# H616 register map
Vendor: Allwinner; Series: H616; File version: 0.1
CPU: other 0, little endian, MPU, no FPU, 0 interrupt priority bits
Registers are 32-bit, read-write, reset 0x0 unless marked. A register's access mark holds for its fields unless they carry their own. Offsets are from the block's base; [hi:lo] are bit positions; lines under a group give offsets from that group; {n}, {i} and the like mark numbered series; 'fields as' and 'values as' point back to an identical list.

## TCON_TV0
Base 0x06515000
Same registers: TCON_TV1 0x06516000
0x00 TV_GCTL_REG — TV Global Control Register
  [31] TV_EN — 0: Disable 1: Enable When it is disabled, the module will be reset to idle state.
    0=Disable; 1=Enable When it is disabled, the module will be reset to idle state
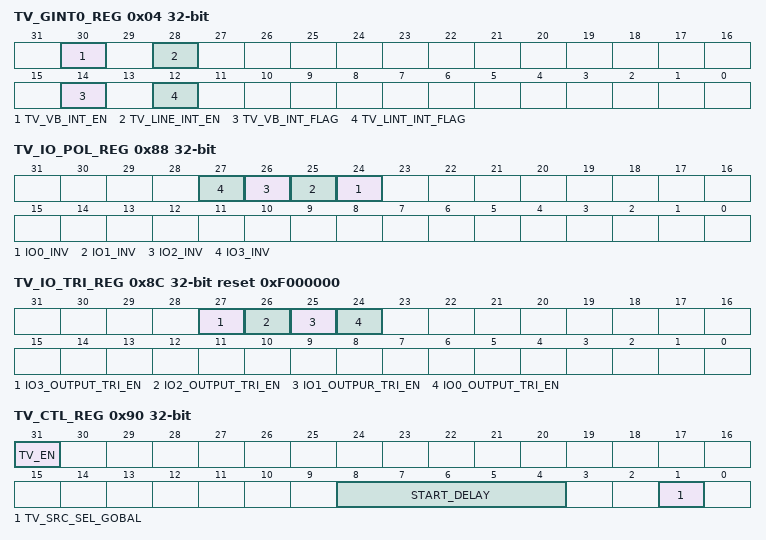
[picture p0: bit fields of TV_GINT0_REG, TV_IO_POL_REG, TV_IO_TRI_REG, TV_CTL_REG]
0x04 TV_GINT0_REG — TV Global Interrupt Register0
  [30] TV_VB_INT_EN — 0: Disable 1: Enable Enable the Vb interrupt.
    0=Disable; 1=Enable Enable the Vb interrupt
  [28] TV_LINE_INT_EN — 0: Disable 1: Enable Enable the line interrupt.
    0=Disable; 1=Enable Enable the line interrupt
  [14] TV_VB_INT_FLAG — Assert during vertical no-display period every frame. Write 0 to clear it.
  [12] TV_LINT_INT_FLAG — Trigger when SY1 match the current TV scan line Write 0 to clear it.
0x08 TV_GINT1_REG — TV Global Interrupt Register1
  [11:0] TV_LINE_INT_NUM — Scan line for TV line trigger(including inactive lines) Setting it for the specified line of trigger 1.
0x40 TV_SRC_CTL_REG — TV Source Control Register
  [2:0] TV_SRC_SEL — 000: DE 001: Color Check 010: Grayscale Check 011: Black by White Check 100: Reserved 101: Reserved 111: Gridding Check
    0=DE; 1=Color Check; 2=Grayscale Check; 3=Black by White Check; 7=Gridding Check
0x88 TV_IO_POL_REG — TV IO Polarity Register
  [n+24] IO{n}_INV (n=0..3) — 0: Not invert 1: Invert Enable invert function of IO{n}.
    0=Not_invert; 1=Invert Enable invert function of IO{n}
0x8C TV_IO_TRI_REG reset 0xF000000 — TV IO Control Register
  [27] IO3_OUTPUT_TRI_EN — 1: Disable 0: Enable Enable the output of IO3.
    1=Disable; 0=Enable Enable the output of IO3
  [26] IO2_OUTPUT_TRI_EN — 1: Disable 0: Enable Enable the output of IO2.
    1=Disable; 0=Enable Enable the output of IO2
  [25] IO1_OUTPUR_TRI_EN — 1: Disable 0: Enable Enable the output of IO1.
    1=Disable; 0=Enable Enable the output of IO1
  [24] IO0_OUTPUT_TRI_EN — 1: Disable 0: Enable Enable the output of IO0.
    1=Disable; 0=Enable Enable the output of IO0
0x90 TV_CTL_REG — TV Control Register
  [31] TV_EN — 0: Disable 1: Enable
    0=Disable; 1=Enable
  [8:4] START_DELAY — This is for DE0 and DE1.
  [1] TV_SRC_SEL_GOBAL — 0: reserved 1: BLUE data
    1=BLUE_data
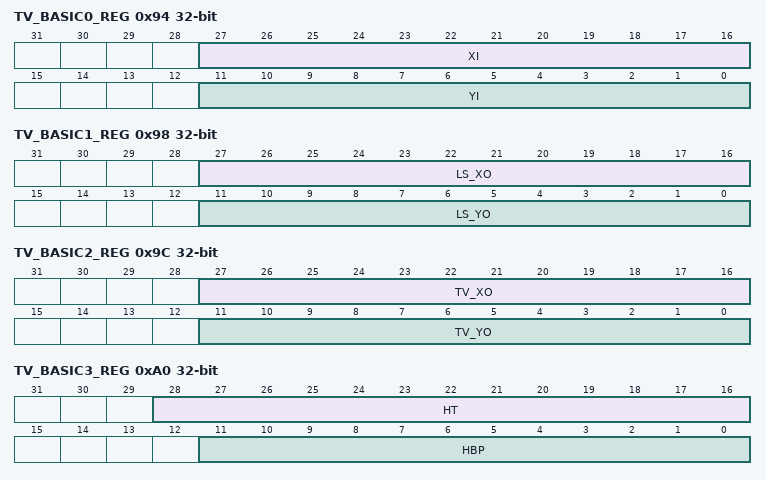
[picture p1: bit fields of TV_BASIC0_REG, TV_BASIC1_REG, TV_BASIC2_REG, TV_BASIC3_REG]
0x94 TV_BASIC0_REG — TV Basic Timing Register0
  [27:16] XI — source width is X+1
  [11:0] YI — source height is Y+1
0x98 TV_BASIC1_REG — TV Basic Timing Register1
  [27:16] LS_XO — Width is LS_XO+1
  [11:0] LS_YO — Width is LS_YO+1
0x9C TV_BASIC2_REG — TV Basic Timing Register2
  [27:16] TV_XO — Width is TV_XO+1
  [11:0] TV_YO — Height is TV_YO+1
0xA0 TV_BASIC3_REG — TV Basic Timing Register3
  [28:16] HT — Horizontal total time T = (HT+1) * T
  [11:0] HBP — Horizontal back porch T = (HBP +1) * T
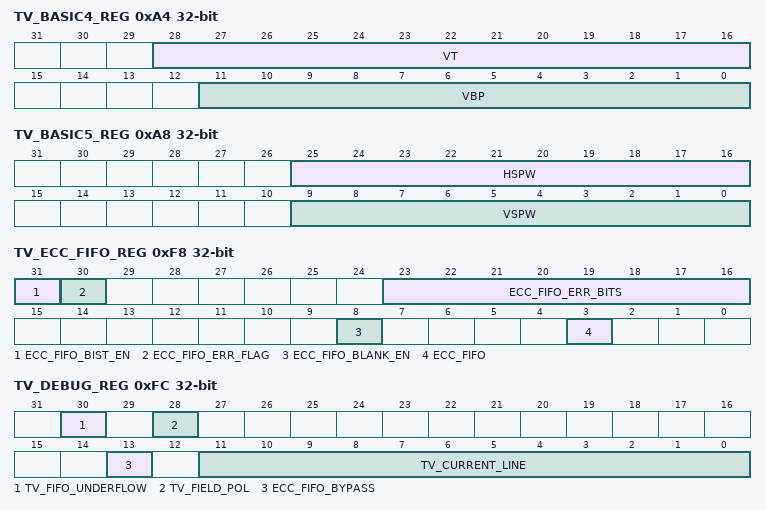
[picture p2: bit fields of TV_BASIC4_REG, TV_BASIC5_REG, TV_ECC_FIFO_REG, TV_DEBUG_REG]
0xA4 TV_BASIC4_REG — TV Basic Timing Register4
  [28:16] VT — Vertical total time (in HD line) T = VT/2 * T
  [11:0] VBP — Vertical back porch (in HD line) T = (VBP +1) * T
0xA8 TV_BASIC5_REG — TV Basic Timing Register5
  [25:16] HSPW — Horizontal Sync Pulse Width (in dclk) T = (HSPW+1) * T HT> (HSPW+1)
  [9:0] VSPW — Vertical Sync Pulse Width (in lines) T = (VSPW+1) * T VT/2 > (VSPW+1)
0xF8 TV_ECC_FIFO_REG — TV ECC FIFO Register
  [31] ECC_FIFO_BIST_EN — 0: Disable 1: Enable Enable ECC FIFO BIST test function.
    0=Disable; 1=Enable Enable ECC FIFO BIST test function
  [30] ECC_FIFO_ERR_FLAG ro — Indicates the error information in ECC FIFO.
  [23:16] ECC_FIFO_ERR_BITS ro — Indicates the error information in ECC FIFO.
  [8] ECC_FIFO_BLANK_EN — 0: Disable ECC function in blanking 1: Enable ECC function in blanking ECC function is tent to trigger in blanking area at HV mode, set `0` when in HV mode.
    0=Disable ECC function in blanking; 1=Enable ECC function in blanking ECC function is tent to trigger in blanking area at HV mode, set `0` when in HV mode
  [3] ECC_FIFO — 0:Enable 1:Disable Enable ECC FIFO function.
0xFC TV_DEBUG_REG — TV Debug Register
  [30] TV_FIFO_UNDERFLOW ro — 0: Not underflow 1: Underflow The flag shows whether the FIFOs in underflow status.
    0=Not_underflow; 1=Underflow The flag shows whether the FIFOs in underflow status
  [28] TV_FIELD_POL ro — 0: Second field 1: First field The flag indicates the current field polarity.
    0=Second; 1=First field The flag indicates the current field polarity
  [13] ECC_FIFO_BYPASS — 0: Used 1: Bypass Setup that whether to bypass ECC FIFO.
    0=Used; 1=Bypass Setup that whether to bypass ECC FIFO
  [11:0] TV_CURRENT_LINE ro — Current scan line.
0x100 TV_CEU_CTL_REG — TV CEU Control Register
  [31] CEU_EN — 0: Bypass 1: Enable Enable CEU function.
    0=Bypass; 1=Enable Enable CEU function
{0x110+4i} TV_CEU_COEF_MUL_REG_{i} (i=0..2) — TV CEU Coefficient MUL Register(N=0,1,2,4,5,6,8,9,10)
  [8] CEU_COEF_MUL_VALUE — CEU_Coef_Mul_Value only can be 0 or 1. REG Map: N=0: Rr N=1: Rg N=2: Rb N=4: Gr N=5: Gg N=6: Gb N=8: Br N=9: Bg N=10: Bb
{0x110+4i} TV_CEU_COEF_MUL_REG_{i} (i=4..6) — TV CEU Coefficient MUL Register(N=0,1,2,4,5,6,8,9,10)
  fields as TV_CEU_COEF_MUL_REG_0
{0x110+4i} TV_CEU_COEF_MUL_REG_{i} (i=8..10) — TV CEU Coefficient MUL Register(N=0,1,2,4,5,6,8,9,10)
  fields as TV_CEU_COEF_MUL_REG_0
{0x140+4i} _N[{i}] (i=0..2) group
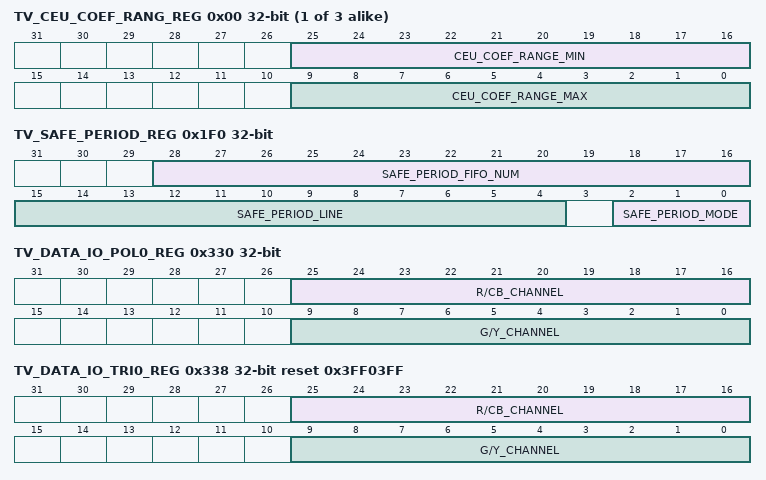
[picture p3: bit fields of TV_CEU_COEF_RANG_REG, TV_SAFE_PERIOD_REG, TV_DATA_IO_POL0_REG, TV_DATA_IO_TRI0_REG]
  0x00 TV_CEU_COEF_RANG_REG — TV CEU Coefficient Range Register(N=0,1,2)
    [25:16] CEU_COEF_RANGE_MIN — Unsigned 10-bit value, range of [0,1023]
    [9:0] CEU_COEF_RANGE_MAX — Unsigned 10-bit value, range of [0,1023]
  0x1C4 TV_FILL_BEGIN_REG — TV Fill Data Begin Register
    [23:0] FILL_BEGIN — Set the begin point of the fill data area.
  0x1C8 TV_FILL_END_REG — TV Fill Data End Register
    [23:0] FILL_END — Set the end point of the fill data area.
  0x1CC TV_FILL_DATA_REG — TV Fill Data Value Register
    [29:0] FILL_VALUE — Set the data value which is used to fill into the blanking area between two frames in HDMI 3D mode.
0x1F0 TV_SAFE_PERIOD_REG — TV Safe Period Register
  [28:16] SAFE_PERIOD_FIFO_NUM — When the data length in line buffer is more than SAFE_PERIOD_FIFO_NUM,LCD controller will allow dram controller to stop working to change frequency.
  [15:4] SAFE_PERIOD_LINE — Set a fixed line and during the line time,LCD controller allow dram controller to change frequency.The fixed line should be set in the blanking area.
  [2:0] SAFE_PERIOD_MODE — Select the save mode 000: unsafe 001: safe 010: safe at FIFO_CURR_NUM > SAFE_PERIOD_FIFO_NUM 011: safe at 2 and safe at sync active 100: safe at line
0x300 TV_FILL_CTL_REG — TV Fill Data Control Register
  [31] TV_FILL_EN — 0: Bypass 1: Enable Enable the fill data function in blanking area. This is only used in HDMI 3D mode.
    0=Bypass; 1=Enable Enable the fill data function in blanking area. This is only used in HDMI 3D mode.
0x330 TV_DATA_IO_POL0_REG — TV Data IO Polarity0 Register
  [25:16] R/CB_CHANNEL — R/Cb Channel Data_Inv [bit9:0 ] 0: normal polarity 1: invert the specify output
  [9:0] G/Y_CHANNEL — G/Y Channel Data_Inv [bit9:0 ] 0: normal polarity 1: invert the specify output
0x334 TV_DATA_IO_POL1_REG — TV Data IO Polarity1 Register
  [25:16] B/CR_CHANNEL — B/Cr Channel Data_Inv 0: normal polarity 1: invert the specify output
0x338 TV_DATA_IO_TRI0_REG reset 0x3FF03FF — TV Data IO Trigger0 Register
  [25:16] R/CB_CHANNEL — R/Cb Channel Data_Output_Tri_En 1: disable 0: enable Only higher 6-bit is valid.
  [9:0] G/Y_CHANNEL — G/Y Channel Data_Output_Tri_En 1: disable 0: enable Only higher 6-bit is valid.
0x33C TV_DATA_IO_TRI1_REG reset 0x3FF0000 — TV Data IO Trigger1 Register
  [25:16] B/CR_CHANNEL — B/Cr Channel Data_Output_Tri_En 1: disable 0: enable Only higher 6-bit is valid.
0x340 TV_PIXELDEPTH_MODE_REG — TV Pixel-depth Mode Register
  [0] COLORBAR — Colorbar Pixeldepth mode(The bit is valid only when Colorbar output) 0: 8-bit mode When data source is colorbar, the 8-bit mode of colorbar pattern is transferred. 1: 10-bit mode When data source is colorbar, the 10-bit mode of colorbar pattern is transferred.
    0=8-bit mode When data source is colorbar, the 8-bit mode of colorbar pattern is transferred; 1=10-bit mode When data source is colorbar, the 10-bit mode of colorbar pattern is transferred
